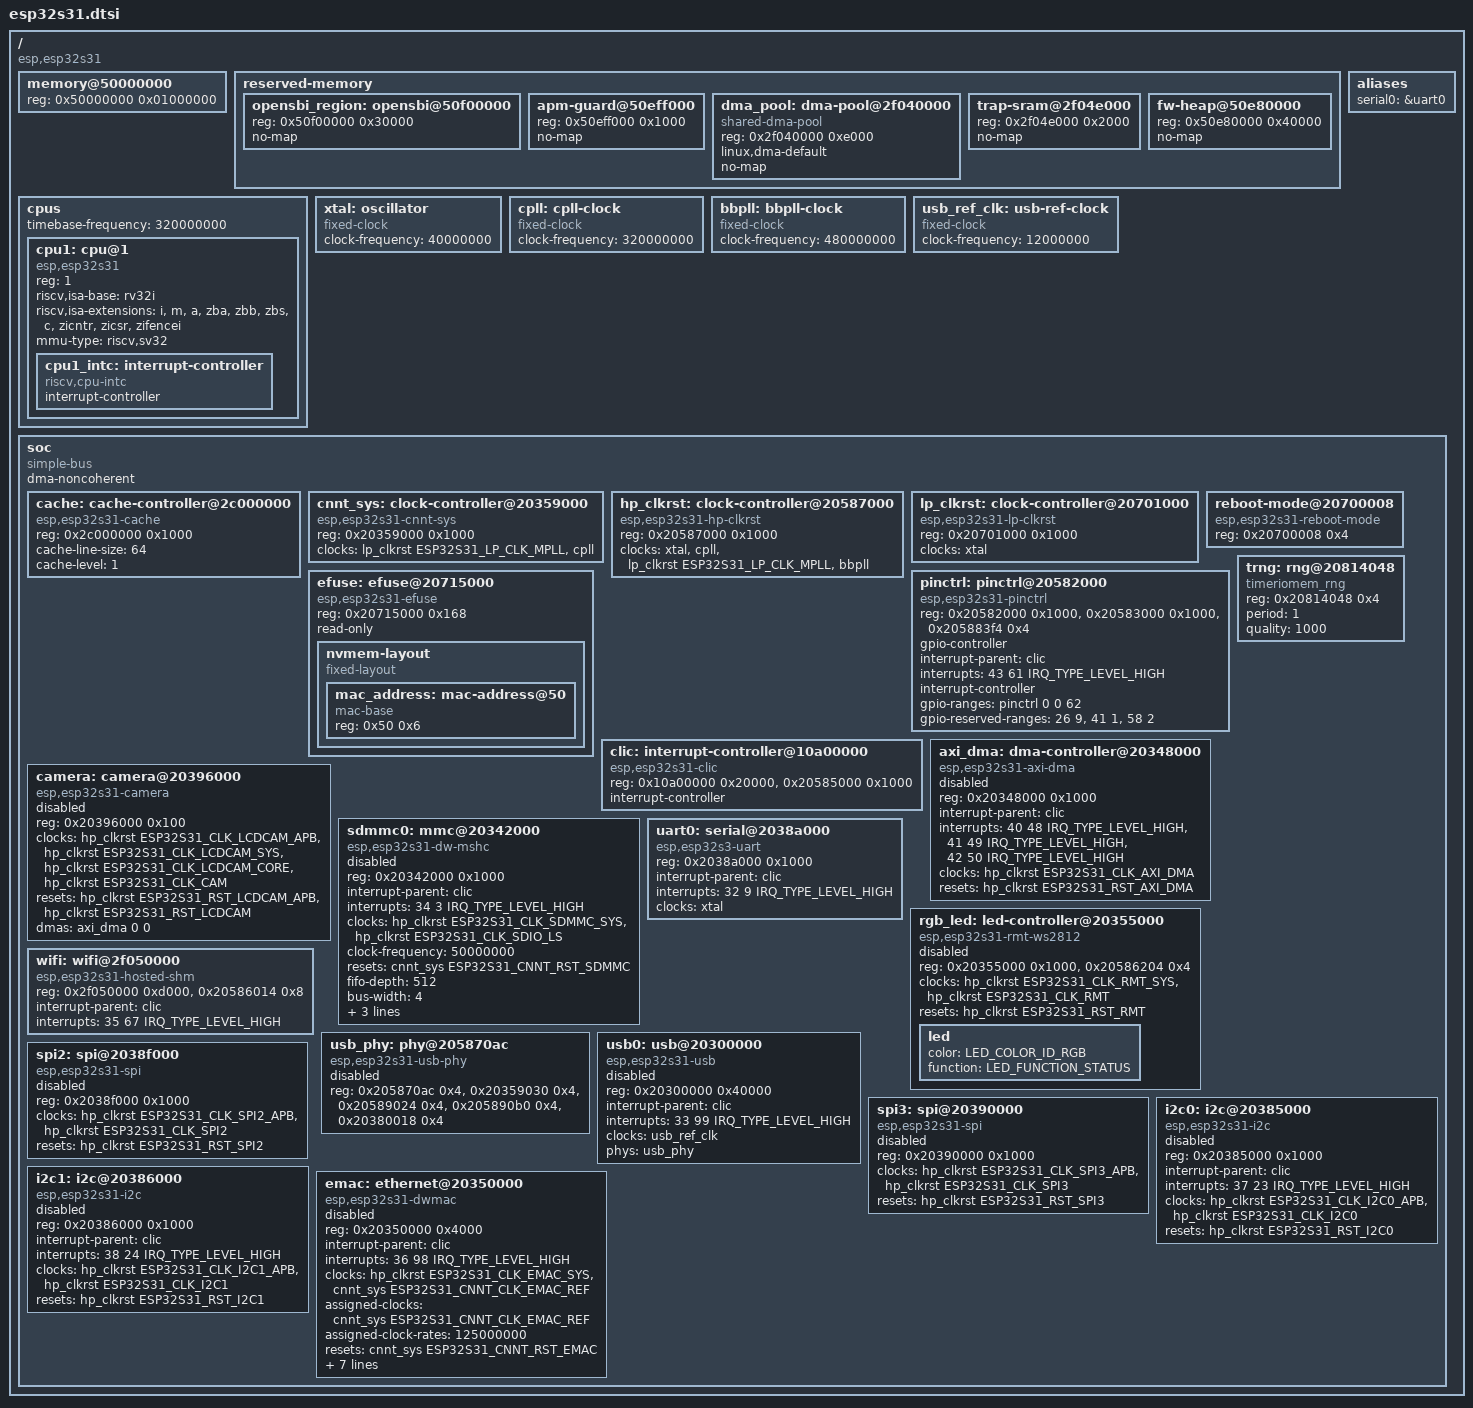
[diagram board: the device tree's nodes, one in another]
// SPDX-License-Identifier: GPL-2.0+
/*
 * Espressif ESP32-S31 minimal device tree.
 * Author: Marco Müller <hello@annoyedmilk.ch>
 */

#include <dt-bindings/clock/esp32s31-clk.h>
#include <dt-bindings/interrupt-controller/irq.h>
#include <dt-bindings/leds/common.h>
#include <dt-bindings/pinctrl/esp32s31-pinctrl.h>

/ {
	#address-cells = <1>;
	#size-cells = <1>;
	compatible = "esp,esp32s31";

	memory@50000000 {
		device_type = "memory";
		/* 16 MiB PSRAM */
		reg = <0x50000000 0x01000000>;
	};

	reserved-memory {
		#address-cells = <1>;
		#size-cells = <1>;
		ranges;

		/* M-mode firmware.  Linux must never map or allocate it. */
		opensbi_region: opensbi@50f00000 {
			reg = <0x50f00000 0x30000>;
			no-map;
		};

		/* HP_APM: 0x50effffc, the word below OpenSBI, is M-mode only. */
		apm-guard@50eff000 {
			reg = <0x50eff000 0x1000>;
			no-map;
		};

		/* Sv32 has no uncached mapping: coherent memory is in SRAM. */
		dma_pool: dma-pool@2f040000 {
			compatible = "shared-dma-pool";
			reg = <0x2f040000 0xe000>;
			linux,dma-default;
			no-map;
		};

		/* The kernel trap code, CONFIG_RISCV_TRAP_SRAM_PHYS. */
		trap-sram@2f04e000 {
			reg = <0x2f04e000 0x2000>;
			no-map;
		};

		/* The heap of the radio firmware on hart 0 (main.c of the loader). */
		fw-heap@50e80000 {
			reg = <0x50e80000 0x40000>;
			no-map;
		};
	};

	aliases {
		serial0 = &uart0;
	};

	cpus {
		#address-cells = <1>;
		#size-cells = <0>;
		timebase-frequency = <320000000>;

		/* Hart 0 runs the ESP-IDF firmware; Linux uses hart 1. */
		cpu1: cpu@1 {
			device_type = "cpu";
			compatible = "esp,esp32s31", "riscv";
			reg = <1>;
			riscv,isa-base = "rv32i";
			riscv,isa-extensions = "i", "m", "a", "zba", "zbb",
					       "zbs", "c", "zicntr", "zicsr",
					       "zifencei";
			mmu-type = "riscv,sv32";
			cpu1_intc: interrupt-controller {
				#interrupt-cells = <1>;
				interrupt-controller;
				compatible = "riscv,cpu-intc";
			};
		};
	};

	xtal: oscillator {
		compatible = "fixed-clock";
		#clock-cells = <0>;
		clock-frequency = <40000000>;
	};

	/* The hardware sets the CPLL to 320 MHz. */
	cpll: cpll-clock {
		compatible = "fixed-clock";
		#clock-cells = <0>;
		clock-frequency = <320000000>;
	};

	bbpll: bbpll-clock {
		compatible = "fixed-clock";
		#clock-cells = <0>;
		clock-frequency = <480000000>;
	};

	/* The PHY driver switches the 12 MHz USB reference clock on and off. */
	usb_ref_clk: usb-ref-clock {
		compatible = "fixed-clock";
		#clock-cells = <0>;
		clock-frequency = <12000000>;
	};

	soc {
		#address-cells = <1>;
		#size-cells = <1>;
		compatible = "simple-bus";
		ranges;
		/* No bus master snoops the D-cache: DMA uses the sync engine. */
		dma-noncoherent;

		cache: cache-controller@2c000000 {
			compatible = "esp,esp32s31-cache";
			reg = <0x2c000000 0x1000>;
			cache-line-size = <64>;
			cache-level = <1>;
		};

		cnnt_sys: clock-controller@20359000 {
			compatible = "esp,esp32s31-cnnt-sys";
			reg = <0x20359000 0x1000>;
			clocks = <&lp_clkrst ESP32S31_LP_CLK_MPLL>, <&cpll>;
			clock-names = "mpll", "cpll";
			#clock-cells = <1>;
			#reset-cells = <1>;
		};

		hp_clkrst: clock-controller@20587000 {
			compatible = "esp,esp32s31-hp-clkrst";
			reg = <0x20587000 0x1000>;
			clocks = <&xtal>, <&cpll>, <&lp_clkrst ESP32S31_LP_CLK_MPLL>,
				 <&bbpll>;
			clock-names = "xtal", "cpll", "mpll", "bbpll";
			#clock-cells = <1>;
			#reset-cells = <1>;
		};

		lp_clkrst: clock-controller@20701000 {
			compatible = "esp,esp32s31-lp-clkrst";
			reg = <0x20701000 0x1000>;
			clocks = <&xtal>;
			clock-names = "xtal";
			#clock-cells = <1>;
		};

		reboot-mode@20700008 {
			compatible = "esp,esp32s31-reboot-mode";
			reg = <0x20700008 0x4>;
		};

		efuse: efuse@20715000 {
			compatible = "esp,esp32s31-efuse";
			reg = <0x20715000 0x168>;
			read-only;

			nvmem-layout {
				compatible = "fixed-layout";
				#address-cells = <1>;
				#size-cells = <1>;

				/* 0 Wi-Fi, 1 Wi-Fi AP, 2 Bluetooth, 3 Ethernet */
				mac_address: mac-address@50 {
					compatible = "mac-base";
					reg = <0x50 0x6>;
					#nvmem-cell-cells = <1>;
				};
			};
		};

		pinctrl: pinctrl@20582000 {
			compatible = "esp,esp32s31-pinctrl";
			reg = <0x20582000 0x1000>, <0x20583000 0x1000>,
			      <0x205883f4 0x4>;
			reg-names = "iomux", "gpio", "cnnt";
			gpio-controller;
			#gpio-cells = <2>;
			interrupt-parent = <&clic>;
			interrupts = <43 61 IRQ_TYPE_LEVEL_HIGH>;
			interrupt-controller;
			#interrupt-cells = <2>;
			#address-cells = <0>;
			gpio-ranges = <&pinctrl 0 0 62>;
			/* Flash, USB Serial/JTAG (33/34), 41 (no pin), UART0. */
			gpio-reserved-ranges = <26 9>, <41 1>, <58 2>;
		};

		clic: interrupt-controller@10a00000 {
			#interrupt-cells = <3>;
			#address-cells = <0>;
			compatible = "esp,esp32s31-clic";
			reg = <0x10a00000 0x20000>, <0x20585000 0x1000>;
			reg-names = "clic", "intmatrix";
			interrupt-controller;
		};

		axi_dma: dma-controller@20348000 {
			compatible = "esp,esp32s31-axi-dma";
			reg = <0x20348000 0x1000>;
			interrupt-parent = <&clic>;
			interrupts = <40 48 IRQ_TYPE_LEVEL_HIGH>,
				     <41 49 IRQ_TYPE_LEVEL_HIGH>,
				     <42 50 IRQ_TYPE_LEVEL_HIGH>;
			clocks = <&hp_clkrst ESP32S31_CLK_AXI_DMA>;
			resets = <&hp_clkrst ESP32S31_RST_AXI_DMA>;
			#dma-cells = <2>;
			status = "disabled";
		};

		camera: camera@20396000 {
			compatible = "esp,esp32s31-camera";
			reg = <0x20396000 0x100>;
			clocks = <&hp_clkrst ESP32S31_CLK_LCDCAM_APB>,
				 <&hp_clkrst ESP32S31_CLK_LCDCAM_SYS>,
				 <&hp_clkrst ESP32S31_CLK_LCDCAM_CORE>,
				 <&hp_clkrst ESP32S31_CLK_CAM>;
			clock-names = "apb", "sys", "core", "cam";
			resets = <&hp_clkrst ESP32S31_RST_LCDCAM_APB>,
				 <&hp_clkrst ESP32S31_RST_LCDCAM>;
			dmas = <&axi_dma 0 0>;
			dma-names = "rx";
			status = "disabled";
		};

		sdmmc0: mmc@20342000 {
			compatible = "esp,esp32s31-dw-mshc", "snps,dw-mshc";
			reg = <0x20342000 0x1000>;
			interrupt-parent = <&clic>;
			interrupts = <34 3 IRQ_TYPE_LEVEL_HIGH>;
			clocks = <&hp_clkrst ESP32S31_CLK_SDMMC_SYS>,
				 <&hp_clkrst ESP32S31_CLK_SDIO_LS>;
			clock-names = "biu", "ciu";
			/* The card clock comes from 50 MHz, as with ESP-IDF. */
			clock-frequency = <50000000>;
			resets = <&cnnt_sys ESP32S31_CNNT_RST_SDMMC>;
			reset-names = "reset";
			fifo-depth = <512>;
			bus-width = <4>;
			cap-sd-highspeed;
			no-1-8-v;
			disable-wp;
			status = "disabled";
		};

		uart0: serial@2038a000 {
			compatible = "esp,esp32s3-uart";
			reg = <0x2038a000 0x1000>;
			interrupt-parent = <&clic>;
			interrupts = <32 9 IRQ_TYPE_LEVEL_HIGH>;
			clocks = <&xtal>;
		};

		/* WS2812 on RMT channel 0; the second reg powers the RMT RAM. */
		rgb_led: led-controller@20355000 {
			compatible = "esp,esp32s31-rmt-ws2812";
			reg = <0x20355000 0x1000>, <0x20586204 0x4>;
			clocks = <&hp_clkrst ESP32S31_CLK_RMT_SYS>,
				 <&hp_clkrst ESP32S31_CLK_RMT>;
			clock-names = "sys", "core";
			resets = <&hp_clkrst ESP32S31_RST_RMT>;
			status = "disabled";

			led {
				color = <LED_COLOR_ID_RGB>;
				function = LED_FUNCTION_STATUS;
			};
		};

		/* The data register of the TRNG, which the loader starts. */
		trng: rng@20814048 {
			compatible = "timeriomem_rng";
			reg = <0x20814048 0x4>;
			period = <1>;
			quality = <1000>;
		};

		/* ESP-Hosted on hart 0: SRAM rings, FROM_CPU_1/2 doorbells. */
		wifi: wifi@2f050000 {
			compatible = "esp,esp32s31-hosted-shm";
			reg = <0x2f050000 0xd000>, <0x20586014 0x8>;
			reg-names = "shm", "doorbell";
			interrupt-parent = <&clic>;
			interrupts = <35 67 IRQ_TYPE_LEVEL_HIGH>;
		};

		usb_phy: phy@205870ac {
			compatible = "esp,esp32s31-usb-phy";
			reg = <0x205870ac 0x4>, <0x20359030 0x4>,
			      <0x20589024 0x4>, <0x205890b0 0x4>,
			      <0x20380018 0x4>;
			reg-names = "clkrst", "cnnt", "usb-ctrl", "otghs-ctrl",
				    "utmi-fc06";
			#phy-cells = <0>;
			status = "disabled";
		};

		usb0: usb@20300000 {
			compatible = "esp,esp32s31-usb", "snps,dwc2";
			/* With the FIFO windows at 0x1000 * (channel + 1). */
			reg = <0x20300000 0x40000>;
			interrupt-parent = <&clic>;
			interrupts = <33 99 IRQ_TYPE_LEVEL_HIGH>;
			clocks = <&usb_ref_clk>;
			clock-names = "otg";
			phys = <&usb_phy>;
			phy-names = "usb2-phy";
			status = "disabled";
		};

		spi2: spi@2038f000 {
			compatible = "esp,esp32s31-spi";
			reg = <0x2038f000 0x1000>;
			clocks = <&hp_clkrst ESP32S31_CLK_SPI2_APB>,
				 <&hp_clkrst ESP32S31_CLK_SPI2>;
			clock-names = "apb", "core";
			resets = <&hp_clkrst ESP32S31_RST_SPI2>;
			#address-cells = <1>;
			#size-cells = <0>;
			status = "disabled";
		};

		spi3: spi@20390000 {
			compatible = "esp,esp32s31-spi";
			reg = <0x20390000 0x1000>;
			clocks = <&hp_clkrst ESP32S31_CLK_SPI3_APB>,
				 <&hp_clkrst ESP32S31_CLK_SPI3>;
			clock-names = "apb", "core";
			resets = <&hp_clkrst ESP32S31_RST_SPI3>;
			#address-cells = <1>;
			#size-cells = <0>;
			status = "disabled";
		};

		i2c0: i2c@20385000 {
			compatible = "esp,esp32s31-i2c";
			reg = <0x20385000 0x1000>;
			interrupt-parent = <&clic>;
			interrupts = <37 23 IRQ_TYPE_LEVEL_HIGH>;
			clocks = <&hp_clkrst ESP32S31_CLK_I2C0_APB>,
				 <&hp_clkrst ESP32S31_CLK_I2C0>;
			clock-names = "apb", "core";
			resets = <&hp_clkrst ESP32S31_RST_I2C0>;
			#address-cells = <1>;
			#size-cells = <0>;
			status = "disabled";
		};

		i2c1: i2c@20386000 {
			compatible = "esp,esp32s31-i2c";
			reg = <0x20386000 0x1000>;
			interrupt-parent = <&clic>;
			interrupts = <38 24 IRQ_TYPE_LEVEL_HIGH>;
			clocks = <&hp_clkrst ESP32S31_CLK_I2C1_APB>,
				 <&hp_clkrst ESP32S31_CLK_I2C1>;
			clock-names = "apb", "core";
			resets = <&hp_clkrst ESP32S31_RST_I2C1>;
			#address-cells = <1>;
			#size-cells = <0>;
			status = "disabled";
		};

		/* Small RX FIFO; a burst over 16 beats to PSRAM stops hart 0. */
		emac: ethernet@20350000 {
			compatible = "esp,esp32s31-dwmac", "snps,dwmac-3.70a";
			reg = <0x20350000 0x4000>;
			interrupt-parent = <&clic>;
			interrupts = <36 98 IRQ_TYPE_LEVEL_HIGH>;
			interrupt-names = "macirq";
			clocks = <&hp_clkrst ESP32S31_CLK_EMAC_SYS>,
				 <&cnnt_sys ESP32S31_CNNT_CLK_EMAC_REF>;
			clock-names = "stmmaceth", "ref";
			/* The TX clock starts at the 1000 Mbit/s rate, not at MPLL/1. */
			assigned-clocks = <&cnnt_sys ESP32S31_CNNT_CLK_EMAC_REF>;
			assigned-clock-rates = <125000000>;
			resets = <&cnnt_sys ESP32S31_CNNT_RST_EMAC>;
			reset-names = "stmmaceth";
			esp,cnnt-sys = <&cnnt_sys>;
			nvmem-cells = <&mac_address 3>;
			nvmem-cell-names = "mac-address";
			snps,pbl = <16>;
			snps,no-pbl-x8;
			snps,aal;
			snps,force_thresh_dma_mode;
			status = "disabled";
		};
	};
};
